# Qorvo_SVD register map
Vendor: Qorvo Inc; Series: ARMCM4; File version: 1.0
Registers are 8-bit, read-write, reset 0x0 unless marked. A register's access mark holds for its fields unless they carry their own. Offsets are from the block's base; [hi:lo] are bit positions; {n}, {i} and the like mark numbered series.

## SPI_M
Base 0x400010D0
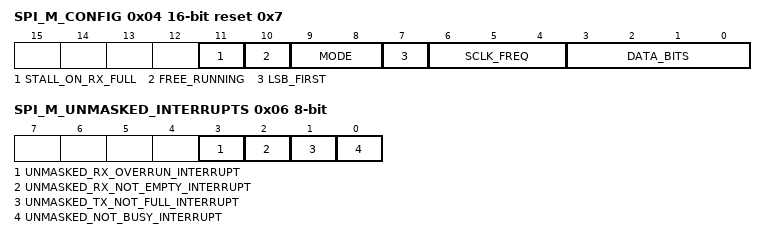
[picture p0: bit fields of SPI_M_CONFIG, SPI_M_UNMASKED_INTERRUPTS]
0x04 SPI_M_CONFIG 16-bit reset 0x7
  [11] STALL_ON_RX_FULL — When enabled, a transfer will be stalled (frozen in the last clock cycle of the word) as long as the rx_data FIFO remains full. This will prevent an rx_overrun from happening.
  [10] FREE_RUNNING — Free running mode, spi transfers are back-to-back triggered, even when no new tx_data is provided. Can be used for capturing PDM outputs.
  [9:8] MODE — Master SPI mode
  [7] LSB_FIRST — Master SPI data order.
  [6:4] SCLK_FREQ — SCLK clock frequency: 32MHz / 2**sclk_freq
  [3:0] DATA_BITS — Number of data bits in an SPI frame - 1 (0x7 = one byte)
0x06 SPI_M_UNMASKED_INTERRUPTS ro
  [3] UNMASKED_RX_OVERRUN_INTERRUPT — Event and unmasked interrupt flag for the occurrence of a rx data buffer overrun event. Set when the rx data buffer is full and new rx data is available. Cleared explicitly by the SW.
  [2] UNMASKED_RX_NOT_EMPTY_INTERRUPT — Status and unmasked interrupt flag for RX buffer not empty. The interrupt is cleared implicitly when reading the last RX data from the buffer.
  [1] UNMASKED_TX_NOT_FULL_INTERRUPT — Status and unmasked interrupt flag for TX buffer not full. The interrupt is cleared implicitly when writing new TX data fills the buffer.
  [0] UNMASKED_NOT_BUSY_INTERRUPT — Status and unmasked interrupt flag for transfer not busy. The interrupt is cleared implicitly when writing new TX data. Active when no transfer ongoing and no data in TX buffer.

## KEYPAD
Base 0x400010E0
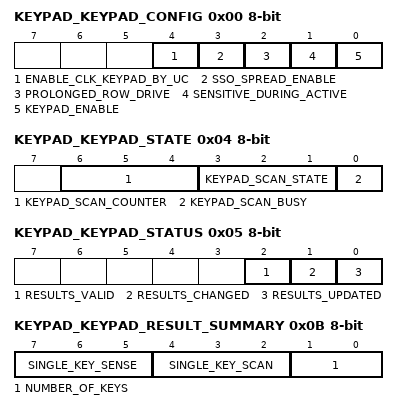
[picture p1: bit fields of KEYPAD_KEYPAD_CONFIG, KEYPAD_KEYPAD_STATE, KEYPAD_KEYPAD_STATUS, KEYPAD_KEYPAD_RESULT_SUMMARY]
0x00 KEYPAD_KEYPAD_CONFIG
  [4] ENABLE_CLK_KEYPAD_BY_UC — Enables clock gating (to be enabled when changing sensitive_during_active setting)
  [3] SSO_SPREAD_ENABLE — Spreads output changes over time to reduce sso effects
  [2] PROLONGED_ROW_DRIVE — When '1', the scan outputs are driven to 0 after the real measurement (debug)
  [1] SENSITIVE_DURING_ACTIVE — When '1' the scan outputs are driven to 0 during active to allow new keypad press to be detected
  [0] KEYPAD_ENABLE — Keypad scan enabled
0x01 KEYPAD_ACTIVE_COLUMNS_CHARGE_PERIOD reset 0xFF
  [7:0] ACTIVE_COLUMNS_CHARGE_PERIOD — Active columns charge period selection: 0=250ns 1=500ns, 2=750ns, ..., FF= disabled
0x02 KEYPAD_PASSIVE_COLUMNS_CHARGE_PERIOD reset 0xFF
  [7:0] PASSIVE_COLUMNS_CHARGE_PERIOD — Passive columns charge period selection: 0=250ns 1=500ns, 2=750ns, ..., FF= disabled
0x03 KEYPAD_ROW_DRIVE_PERIOD
  [7:0] ROW_DRIVE_PERIOD — Time that scan outputs are driven to 0 before measurement is done:0=250ns 1=500ns, 2=750ns, ..., FF = 63750ns
0x04 KEYPAD_KEYPAD_STATE ro
  [6:4] KEYPAD_SCAN_COUNTER — Indicates the row counter of a ongoing keypad scan
  [3:1] KEYPAD_SCAN_STATE — Indicates the state of a ongoing keypad scan
  [0] KEYPAD_SCAN_BUSY — Indicates if a keypad scan is busy
0x05 KEYPAD_KEYPAD_STATUS ro
  [2] RESULTS_VALID — Results valid indication: this bit is set to 0x1 when all of the keypad scan's inputs are connected to the device's input pads. Cleared by writing 0x1 to clear_results_valid
  [1] RESULTS_CHANGED — Results changed indication: this bit is set to 0x1 when one of the scan results is updated and was different from previous value, cleared by writing 0x1 to clear_results_changed
  [0] RESULTS_UPDATED — Results updated indication: this bit is set to 0x1 when one of the scan results is updated, cleared by writing 0x1 to clear_results_updated
0x06 KEYPAD_KEYPAD_SCANS ro
  [7:0] KEYPAD_SCANS — Read back of keypad scan output value
0x07 KEYPAD_KEYPAD_SENSES_ACTIVE_CHARGE ro
  [7:0] KEYPAD_SENSES_ACTIVE_CHARGE — Read back of keypad senses active charge output value
0x08 KEYPAD_KEYPAD_SENSES ro
  [7:0] KEYPAD_SENSES — Read back of keypad senses input value
0x0A KEYPAD_RESULTS_STABLE_COUNTER
  [7:0] RESULTS_STABLE_COUNTER — Counts the number of consecutive times the same result was detected, cleared by writing 0x0
0x0B KEYPAD_KEYPAD_RESULT_SUMMARY
  [7:5] SINGLE_KEY_SENSE — Single key sense (column) number (0...7).
  [4:2] SINGLE_KEY_SCAN — Single key scan (row) number (0...7).
  [1:0] NUMBER_OF_KEYS — Number of keys detected, 0=no key, 1=single key, 2=two keys, 3= more than 2 keys.
{0xC+i} KEYPAD_KEY_VECTOR_{i} (i=0..7)
  [7:0] KEY_VECTOR_{i} — Key sense vector {i}.
0x14 KEYPAD_0X00000014 ro
  [0] UNMASKED_SCAN_DONE_INTERRUPT — Masked interrupt event status, Active when 0x1
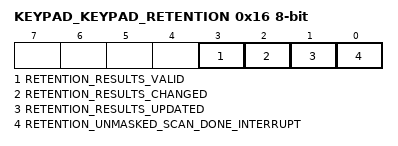
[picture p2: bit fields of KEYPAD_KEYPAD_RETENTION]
0x16 KEYPAD_KEYPAD_RETENTION
  [3] RETENTION_RESULTS_VALID
  [2] RETENTION_RESULTS_CHANGED
  [1] RETENTION_RESULTS_UPDATED
  [0] RETENTION_UNMASKED_SCAN_DONE_INTERRUPT — Retention unmasked keypad interrupt
